# STM32L4x2 register map
File version: 2.3
CPU: CM4 r0p1, little endian, MPU, FPU, 4 interrupt priority bits
Registers are 32-bit, read-write, reset 0x0 unless marked. A register's access mark holds for its fields unless they carry their own. Offsets are from the block's base; [hi:lo] are bit positions; {n}, {i} and the like mark numbered series.

## CRC — Cyclic redundancy check calculation unit
Base 0x40023000
0x00 DR reset 0xFFFFFFFF — Data register
  [31:0] DR — Data register bits
0x00 DR8 8-bit reset 0xFF (alternate view of DR) — Data register - byte sized
  [7:0] DR8 — Data register bits
0x00 DR16 16-bit reset 0xFFFF (alternate view of DR) — Data register - half-word sized
  [15:0] DR16 — Data register bits
0x04 IDR — Independent data register
  [7:0] IDR — General-purpose 8-bit data register bits
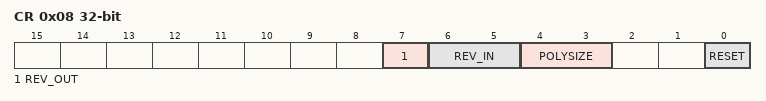
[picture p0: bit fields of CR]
0x08 CR access per field — Control register
  [7] REV_OUT rw — Reverse output data
    0=Normal (Bit order not affected); 1=Reversed (Bit reversed output)
  [6:5] REV_IN rw — Reverse input data
    0=Normal (Bit order not affected); 1=Byte (Bit reversal done by byte); 2=HalfWord (Bit reversal done by half-word); 3=Word (Bit reversal done by word)
  [4:3] POLYSIZE rw — Polynomial size
    0=32-bit polynomial; 1=16-bit polynomial; 2=8-bit polynomial; 3=7-bit polynomial
  [0] RESET wo — RESET bit
    1=Resets the CRC calculation unit and sets the data register to 0xFFFF FFFF
0x10 INIT reset 0xFFFFFFFF — Initial CRC value
  [31:0] INIT — Programmable initial CRC value
0x14 POL reset 0x4C11DB7 — polynomial
  [31:0] POL — Programmable polynomial

## LCD — Liquid crystal display controller
Base 0x40002400
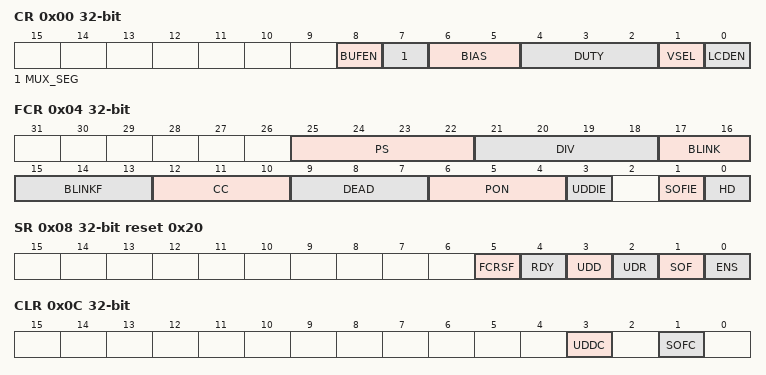
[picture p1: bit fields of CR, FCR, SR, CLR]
0x00 CR — control register
  [8] BUFEN — Voltage output buffer enable
  [7] MUX_SEG — Mux segment enable
  [6:5] BIAS — Bias selector
  [4:2] DUTY — Duty selection
  [1] VSEL — Voltage source selection
  [0] LCDEN — LCD controller enable
0x04 FCR — frame control register
  [25:22] PS — PS 16-bit prescaler
  [21:18] DIV — DIV clock divider
  [17:16] BLINK — Blink mode selection
  [15:13] BLINKF — Blink frequency selection
  [12:10] CC — Contrast control
  [9:7] DEAD — Dead time duration
  [6:4] PON — Pulse ON duration
  [3] UDDIE — Update display done interrupt enable
  [1] SOFIE — Start of frame interrupt enable
  [0] HD — High drive enable
0x08 SR access per field reset 0x20 — status register
  [5] FCRSF ro — LCD Frame Control Register Synchronization flag
  [4] RDY ro — Ready flag
  [3] UDD ro — Update Display Done
  [2] UDR wo — Update display request
  [1] SOF ro — Start of frame flag
  [0] ENS ro
0x0C CLR wo — clear register
  [3] UDDC — Update display done clear
  [1] SOFC — Start of frame flag clear
{0x14+8i} RAM_COM{i} 64-bit (reset mask 0xFFFFFFFF) (i=0..3) — LCD display memory
  [39:0] SEGS — Segment states, one bit per segment, LSB: S00, MSB: S39
{0x14+8i} RAM_COM{i} 64-bit (reset mask 0xFFFFFFFF) (i=4..7) — LCD display memory
  [43:0] SEGS — Segment states, one bit per segment, LSB: S00, MSB: S43

## IWDG — Independent watchdog
Base 0x40003000
0x00 KR 16-bit wo — Key register
  [15:0] KEY — Key value (write only, read 0x0000)
    0x5555=Unlock (Enable access to PR, RLR and WINR registers); 0xAAAA=Feed watchdog with RLR register value; 0xCCCC=Start the watchdog
0x04 PR 16-bit — Prescaler register
  [2:0] PR — Prescaler divider
    0=DivideBy4 (Divider /4); 1=DivideBy8 (Divider /8); 2=DivideBy16 (Divider /16); 3=DivideBy32 (Divider /32); 4=DivideBy64 (Divider /64); 5=DivideBy128 (Divider /128); other=DivideBy256 (Divider /256)
0x08 RLR 16-bit reset 0xFFF — Reload register
  [11:0] RL — Watchdog counter reload value
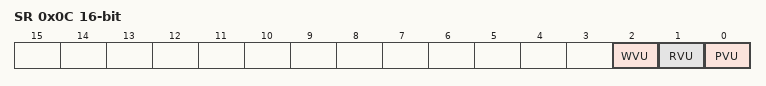
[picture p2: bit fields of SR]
0x0C SR 16-bit ro — Status register
  [2] WVU — Watchdog counter window value update
  [1] RVU — Watchdog counter reload value update
  [0] PVU — Watchdog prescaler value update
0x10 WINR 16-bit reset 0xFFF — Window register
  [11:0] WIN — Watchdog counter window value

## WWDG — System window watchdog
Base 0x40002C00
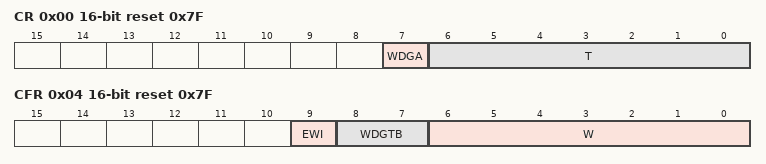
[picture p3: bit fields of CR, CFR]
0x00 CR 16-bit reset 0x7F — Control register
  [7] WDGA — Activation bit
    0=Disabled (Watchdog disabled); 1=Enabled (Watchdog enabled)
  [6:0] T — 7-bit counter (MSB to LSB)
0x04 CFR 16-bit reset 0x7F — Configuration register
  [9] EWI — Early wakeup interrupt
    on write: 1=Enable (interrupt occurs whenever the counter reaches the value 0x40)
  [8:7] WDGTB — Timer base
    0=Div1 (Counter clock (PCLK1 div 4096) div 1); 1=Div2 (Counter clock (PCLK1 div 4096) div 2); 2=Div4 (Counter clock (PCLK1 div 4096) div 4); 3=Div8 (Counter clock (PCLK1 div 4096) div 8)
  [6:0] W — 7-bit window value
0x08 SR 16-bit — Status register
  [0] EWIF write-0-clears — Early wakeup interrupt flag
    on read: 0=Finished (The EWI Interrupt Service Routine has been serviced); 1=Pending (The EWI Interrupt Service Routine has been triggered) | on write: 0=Finished (The EWI Interrupt Service Routine has been serviced)
